# R7FA6T1AD register map
Vendor: Renesas; Series: RA6; File version: 1.0
CPU: CM4 r0p1, little endian, MPU, FPU, VTOR, 4 interrupt priority bits
Registers are 8-bit, read-write, reset 0x0 unless marked. A register's access mark holds for its fields unless they carry their own. Offsets are from the block's base; [hi:lo] are bit positions; {n}, {i} and the like mark numbered series.

## DAC12 — 12-bit D/A converter
Base 0x4005E000
{0x0+2i} DADR{i} (i=0..1) 16-bit — D/A Data Register {i}
  [15:0] DADR — D/A Data RegisterNOTE: When DADPR.DPSEL = 0, the high,order 4 bits are fixed to 0: right justified format. When DADPR.DPSEL = 1, the low,order 4 bits are fixed to 0: left justified format.
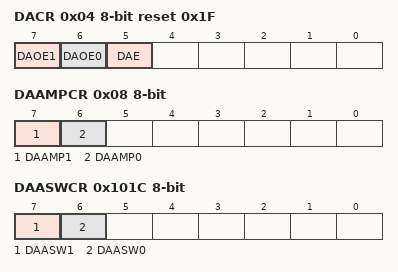
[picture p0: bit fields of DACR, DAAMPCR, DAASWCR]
0x04 DACR reset 0x1F — D/A Control Register
  [7] DAOE1 — D/A Output Enable 1
  [6] DAOE0 — D/A Output Enable 0
  [5] DAE — D/A Enable
0x05 DADPR — DADRm Format Select Register
  [7] DPSEL — DADRm Format Select
0x06 DAADSCR — D/A,A/D Synchronous Start Control Register
  [7] DAADST — D/A,A/D Synchronous Conversion
0x08 DAAMPCR — D/A Output Amplifier Control Register
  [7] DAAMP1 — Amplifier Control 1
  [6] DAAMP0 — Amplifier Control 0
0x101C DAASWCR — D/A Amplifier Stabilization Wait Control Register
  [7] DAASW1 — D/A Amplifier Stabilization Wait 1
  [6] DAASW0 — D/A Amplifier Stabilization Wait 0
0x10C0 DAADUSR — D/A A/D Synchronous Unit Select Register
  [1] AMADSEL1 — A/D Unit 1 Select

## ACMPHS0 — High,Speed Analog Comparator 0
Base 0x40085000
Same registers: ACMPHS1 0x40085100, ACMPHS2 0x40085200, ACMPHS3 0x40085300, ACMPHS4 0x40085400, ACMPHS5 0x40085500
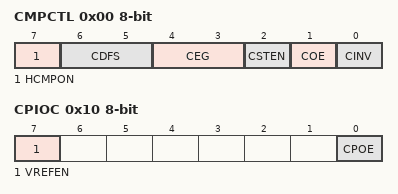
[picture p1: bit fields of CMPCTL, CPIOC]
0x00 CMPCTL — Comparator Control Register
  [7] HCMPON — Comparator operation control
  [6:5] CDFS — Noise filter selection
  [4:3] CEG — Selection of valid edge (Edge selector)
  [2] CSTEN — Interrupt Select
  [1] COE — Comparator output enable
  [0] CINV — Comparator output polarity selection
0x04 CMPSEL0 — Comparator Input Select Register
  [3:0] CMPSEL — Comparator input selection
0x08 CMPSEL1 — Comparator Reference Voltage Select Register
  [3:0] CRVS — Reference voltage selection
0x0C CMPMON ro — Comparator Output Monitor Register
  [0] CMPMON — Comparator output monitor
0x10 CPIOC — Comparator Output Control Register
  [7] VREFEN — Internal Vref enable
  [0] CPOE — Comparator output selection

## TSN — Temperature Sensor
Base 0x4005D000
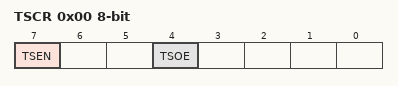
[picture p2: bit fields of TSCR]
0x00 TSCR — Temperature Sensor Control Register
  [7] TSEN — Temperature Sensor Output Enable
  [4] TSOE — Temperature Sensor Enable

## CRC — CRC Calculator
Base 0x40074000
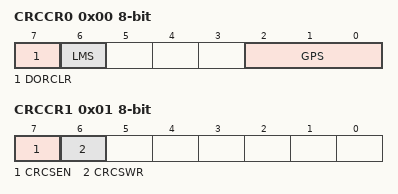
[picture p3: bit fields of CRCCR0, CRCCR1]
0x00 CRCCR0 — CRC Control Register0
  [7] DORCLR wo — CRCDOR Register Clear
  [6] LMS — CRC Calculation Switching
  [2:0] GPS — CRC Generating Polynomial Switching
0x01 CRCCR1 — CRC Control Register1
  [7] CRCSEN — Snoop enable bit
  [6] CRCSWR — Snoop,on,write/read switch bit
0x04 CRCDIR 32-bit — CRC Data Input Register
  [31:0] CRCDIR — Calculation input Data (Case of CRC-32, CRC-32C )
0x04 CRCDIR_BY (alternate view of CRCDIR) — CRC Data Input Register (byte access)
  [7:0] CRCDIR_BY — Calculation input Data ( Case of CRC-8, CRC-16 or CRC,CCITT )
0x08 CRCDOR 32-bit — CRC Data Output Register
  [31:0] CRCDOR — Calculation output Data (Case of CRC-32, CRC-32C )
0x08 CRCDOR_HA 16-bit (alternate view of CRCDOR) — CRC Data Output Register (halfword access)
  [15:0] CRCDOR_HA — Calculation output Data (Case of CRC-16 or CRC,CCITT )
0x08 CRCDOR_BY (alternate view of CRCDOR) — CRC Data Output Register(byte access)
  [7:0] CRCDOR_BY — Calculation output Data (Case of CRC-8 )
0x0C CRCSAR 16-bit — Snoop Address Register
  [13:0] CRCSA — snoop address bitSet the I/O register address to snoop

## ELC — Event Link Controller
Base 0x40041000
0x00 ELCR — Event Link Controller Register
  [7] ELCON — All Event Link Enable
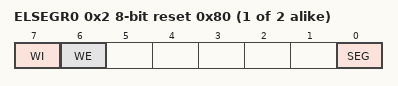
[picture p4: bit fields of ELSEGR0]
{0x2+2i} ELSEGR{i} (i=0..1) reset 0x80 — Event Link Software Event Generation Register {i}
  [7] WI wo — ELSEGR Register Write Disable
  [6] WE — SEG Bit Write Enable
  [0] SEG wo — Software Event Generation
{0x10+4i} ELSR{i} (i=0..18) 16-bit — Event Link Setting Register {i}
  [8:0] ELS — Event Link Select
